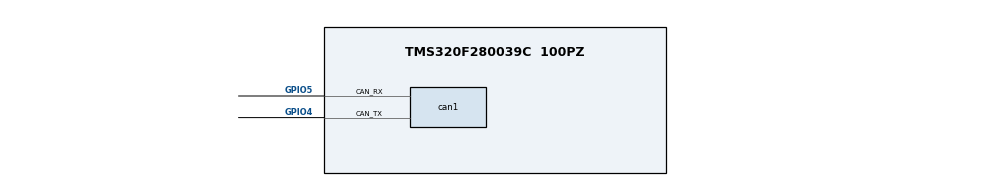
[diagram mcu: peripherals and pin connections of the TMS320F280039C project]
/**
 * These arguments were used when this file was generated. They will be automatically applied on subsequent loads
 * via the GUI or CLI. Run CLI with '--help' for additional information on how to override these arguments.
 * @cliArgs --device "F28003x" --part "F28003x_100PZ" --package "100PZ" --context "system" --product "C2000WARE@5.03.00.00"
 * @v2CliArgs --device "TMS320F280039C" --package "100PZ" --context "system" --product "C2000WARE@5.03.00.00"
 * @versions {"tool":"1.21.0+3721"}
 */

/**
 * Import the modules used in this configuration.
 */
const can  = scripting.addModule("/driverlib/can.js", {}, false);
const can1 = can.addInstance();

/**
 * Write custom configuration values to the imported modules.
 */
can1.$name                 = "CAN0";
can1.msgObjsUsed           = [1];
can1.can.can_rxPin.$assign = "GPIO5";
can1.can.can_txPin.$assign = "GPIO4";
can1.msgObj1.$name         = "msgObj0";
can1.msgObj1.msgID         = 291;
can1.msgObj1.msgType       = "CAN_MSG_OBJ_TYPE_TX";
can1.msgObj1.msgLen        = 8;

/**
 * Pinmux solution for unlocked pins/peripherals. This ensures that minor changes to the automatic solver in a future
 * version of the tool will not impact the pinmux you originally saw.  These lines can be completely deleted in order to
 * re-solve from scratch.
 */
can1.can.$suggestSolution = "CANA";
